# YT9215 register map
Vendor: Motorcomm; Series: YT921x; File version: 1.0
Registers are 32-bit, read-write, no defined reset value unless marked. A register's access mark holds for its fields unless they carry their own. Offsets are from the block's base; [hi:lo] are bit positions; lines under a group give offsets from that group; {n}, {i} and the like mark numbered series.

## METER — Ingress meters
Base 0x00220000
{0x0+4i} PORT_RATE[{i}] (i=0..10) — Per-frame overhead that rate limiting adds to the frame length. Index: port = 0 to 10.
  [4:0] GAP_VALUE — Bytes added per frame for preamble and inter-frame gap. A meter adds them when METER_CTRL.BYTE_MODE_INCLUDE_GAP is set.
0x104 METER_SLOT — Period at which every meter adds tokens to its buckets.
  [11:0] SLOT — Slot length in units of eight core clock periods. SYS_CLK shows the core clock. The smallest allowed value is 80.
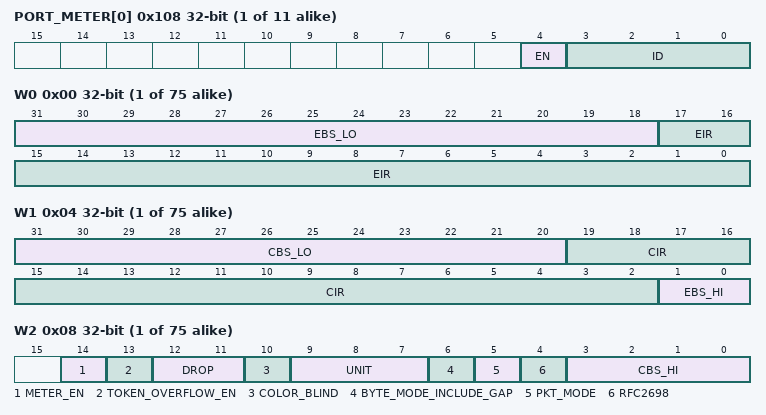
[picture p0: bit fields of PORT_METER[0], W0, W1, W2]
{0x108+4i} PORT_METER[{i}] (i=0..10) — Attaches one of the per-port meters to the receive side of a port. Index: port = 0 to 10.
  [4] EN — Enables ingress rate limiting on the port.
  [3:0] ID — Port meter number n. The meter is entry 64 + n of METER_CTRL.
{0x800+0x10*i} METER_CTRL[{i}] (i=0..74) group — 96-bit configuration of one two-rate token bucket meter. Entries 0 to 63 are general-purpose meters, which :ref:`rate-meter` attaches to ACL rules and VLANs; entries 64 to 74 are the per-port meters. Token arithmetic gives the conversion from bit rates. Index: meter = 0 to 74.
  0x00 W0 — Meter configuration: bits 31 to 0. 96-bit configuration of one two-rate token bucket meter. Entries 0 to 63 are general-purpose meters, which :ref:`rate-meter` attaches to ACL rules and VLANs; entries 64 to 74 are the per-port meters. Token arithmetic gives the conversion from bit rates.
    [31:18] EBS_LO — Excess burst size in tokens. The field crosses the boundary between words 0 and 1.
    [17:0] EIR — Excess information rate in tokens per time slot.
  0x04 W1 — Meter configuration: bits 63 to 32. 96-bit configuration of one two-rate token bucket meter. Entries 0 to 63 are general-purpose meters, which :ref:`rate-meter` attaches to ACL rules and VLANs; entries 64 to 74 are the per-port meters. Token arithmetic gives the conversion from bit rates.
    [31:20] CBS_LO — Committed burst size in tokens. The field crosses the boundary between words 1 and 2.
    [19:2] CIR — Committed information rate in tokens per time slot.
    [1:0] EBS_HI — Excess burst size in tokens. The field crosses the boundary between words 0 and 1.
  0x08 W2 — Meter configuration: bits 95 to 64. 96-bit configuration of one two-rate token bucket meter. Entries 0 to 63 are general-purpose meters, which :ref:`rate-meter` attaches to ACL rules and VLANs; entries 64 to 74 are the per-port meters. Token arithmetic gives the conversion from bit rates.
    [14] METER_EN — Enables the meter.
    [13] TOKEN_OVERFLOW_EN — Tokens that overflow the committed bucket spill into the excess bucket. This meaning is inferred from a comment. The comment on the field reads "RFC4115: yellow use unused green bw".
    [12:11] DROP — Colours that are dropped.
      0=GYR (Drop every frame); 1=YR (Drop yellow and red frames); 2=R (Drop red frames); 3=NONE (Drop nothing and only colour the frame)
    [10] COLOR_BLIND — Ignore the colour the frame already has.
    [9:7] UNIT — Token scale. Every token value is multiplied by 4 to the power of this field.
    [6] BYTE_MODE_INCLUDE_GAP — Add PORT_RATE.GAP_VALUE bytes to each frame in byte mode.
    [5] PKT_MODE — Meter packets. Value 0 meters bytes.
    [4] RFC2698 — Select the algorithm of RFC 2698. Value 0 selects that of RFC 4115.
    [3:0] CBS_HI — Committed burst size in tokens. The field crosses the boundary between words 1 and 2.
{0x1000+8i} METER_STAT[{i}] (i=0..74) group — Current token counts of one meter. The bit layout is not known. Index: meter = 0 to 74.
  0x00 W0 ro — Meter token state: bits 31 to 0. Current token counts of one meter. The bit layout is not known.
    [31:0] VALUE_LO — Layout not known.
  0x04 W1 ro — Meter token state: bits 63 to 32. Current token counts of one meter. The bit layout is not known.
    [31:0] VALUE_HI — Layout not known.
